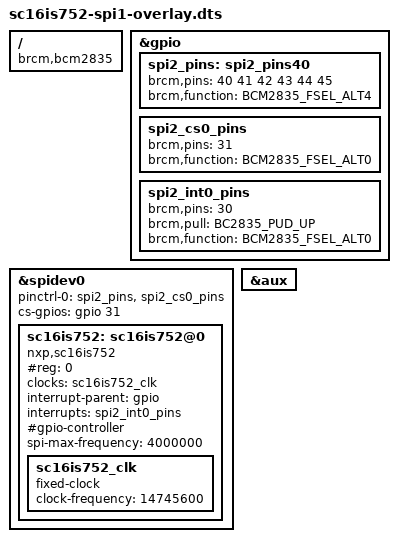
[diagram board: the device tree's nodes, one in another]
/dts-v1/;
/plugin/;

/ {
	compatible = "brcm,bcm2835", "brcm,bcm2708", "brcm,bcm2709";

	fragment@0 {
		target = <&gpio>;
		__overlay__ {

			spi2_pins: spi2_pins40 {
				     brcm,pins = <40 41 42 43 44 45>;
				     brcm,function = <BCM2835_FSEL_ALT4>;
				     };
			spi2_cs0_pins: spi2_cs0_pins {
				brcm,pins = <31>;
				brcm,function = <BCM2835_FSEL_ALT0>; /* output */
			};
			spi2_int0_pins: spi2_int0_pins {
				brcm,pins = <30>;
                                brcm,pull=<BC2835_PUD_UP>;
				brcm,function = <BCM2835_FSEL_ALT0>; /* output */
			};
		};
	};

	fragment@1 {
		target = <&spidev0.2>;
		frag1: __overlay__ {
			#address-cells = <1>;
			#size-cells = <0>;
			pinctrl-names = "default";
			pinctrl-0 = <&spi2_pins &spi2_cs0_pins>;
			cs-gpios = <&gpio 31>;
			status = "okay";

			sc16is752: sc16is752@0 {
				compatible = "nxp,sc16is752";
				#reg = <0>; /* CE0 ?? */
				clocks = <&sc16is752_clk>;
				interrupt-parent = <&gpio>;
				interrupts = <&spi2_int0_pins>; /* IRQ_TYPE_EDGE_FALLING */
				#gpio-controller;
				#gpio-cells = <2>;
				spi-max-frequency = <4000000>;

				sc16is752_clk: sc16is752_clk {
					compatible = "fixed-clock";
					#clock-cells = <0>;
					clock-frequency = <14745600>;
				};
			};
		};
	};

	fragment@2 {
		target = <&aux>;
		__overlay__ {
			status = "okay";
		};
	};

    __overrides__ {
      int_pin = <&sc16is752>,"interrupts:0";
    };
};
